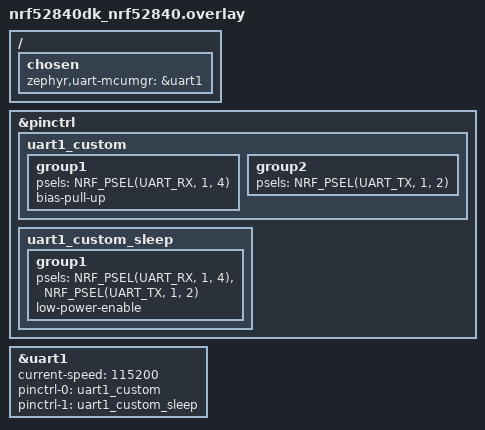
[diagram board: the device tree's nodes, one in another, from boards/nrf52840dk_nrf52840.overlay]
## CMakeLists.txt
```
cmake_minimum_required(VERSION 3.20.0)
# Top-level CMakeLists.txt for the skeleton application.
#
# Copyright (c) 2017 Open Source Foundries Limited
#
# SPDX-License-Identifier: Apache-2.0
#
# This provides a basic application structure suitable for communication using
# mcumgr.  It can be used as a starting point for new applications.

# Standard Zephyr application boilerplate.
find_package(Zephyr REQUIRED HINTS $ENV{ZEPHYR_BASE})
project(rid0)

target_sources(app PRIVATE src/main.c)
target_sources_ifdef(CONFIG_MCUMGR_TRANSPORT_BT app PRIVATE src/bluetooth.c)
target_sources(app PRIVATE src/central.c)
target_sources(app PRIVATE src/common.c)
target_sources(app PRIVATE src/uart.c)
target_sources(app PRIVATE src/mcumgr.c)
```

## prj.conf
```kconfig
# 启用蓝牙主机
CONFIG_BT_CENTRAL=y
CONFIG_LOG=y
CONFIG_BT_SMP=y
CONFIG_BT_GATT_CLIENT=y
CONFIG_CBPRINTF_FP_SUPPORT=y
CONFIG_BT_EXT_ADV=y

# 启用MCUmgr事件回调
CONFIG_MCUMGR_MGMT_NOTIFICATION_HOOKS=y
CONFIG_MCUMGR_GRP_IMG_UPLOAD_CHECK_HOOK=y
CONFIG_MCUMGR_GRP_IMG_STATUS_HOOKS=y

# 启用 UART1 驱动
CONFIG_SERIAL=y

#启用UART1作为升级串口
CONFIG_CONSOLE=y
CONFIG_UART_ASYNC_API=y
CONFIG_UART_0_ASYNC=y

#开启串口传输固件
CONFIG_BASE64=y
CONFIG_MCUMGR_TRANSPORT_UART=y
CONFIG_MCUMGR_TRANSPORT_UART_MTU=1024
CONFIG_MCUMGR_TRANSPORT_SHELL_MTU=1024

# Enable MCUmgr and dependencies.
CONFIG_NET_BUF=y
CONFIG_ZCBOR=y
CONFIG_CRC=y
CONFIG_MCUMGR=y
CONFIG_STREAM_FLASH=y
CONFIG_FLASH_MAP=y

# Some command handlers require a large stack.
CONFIG_SYSTEM_WORKQUEUE_STACK_SIZE=2304
CONFIG_MAIN_STACK_SIZE=2176

# Ensure an MCUboot-compatible binary is generated.
CONFIG_BOOTLOADER_MCUBOOT=y
#Include MCUMGR and the dependencies in the build
CONFIG_BT=y
CONFIG_BT_BROADCASTER=n
CONFIG_BT_OBSERVER=y
CONFIG_LOG=y
CONFIG_BT_PERIPHERAL=n
CONFIG_NCS_SAMPLE_MCUMGR_BT_OTA_DFU=n
CONFIG_MCUMGR_TRANSPORT_BT=n     # BLE升级

# Enable flash operations.
CONFIG_FLASH=y

# Required by the `taskstat` command.
CONFIG_THREAD_MONITOR=y

# Support for taskstat command
CONFIG_MCUMGR_GRP_OS_TASKSTAT=y

# Enable statistics and statistic names.
CONFIG_STATS=y
CONFIG_STATS_NAMES=y

# Enable most core commands.
CONFIG_FLASH=y
CONFIG_IMG_MANAGER=y
CONFIG_MCUMGR_GRP_IMG=y
CONFIG_MCUMGR_GRP_OS=y
CONFIG_MCUMGR_GRP_STAT=y

# Enable logging
CONFIG_LOG=y
CONFIG_MCUBOOT_UTIL_LOG_LEVEL_WRN=y

# Disable debug logging
CONFIG_LOG_MAX_LEVEL=3
```

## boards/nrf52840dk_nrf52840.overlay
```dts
/* RID0 — uart1 引脚: TX=P1.02, RX=P1.04 */
/* mcumgr DFU on uart1 */

/ {
	chosen {
		zephyr,uart-mcumgr = &uart1;
	};
};

&pinctrl {
	uart1_custom: uart1_custom {
		group1 {
			psels = <NRF_PSEL(UART_RX, 1, 4)>;
			bias-pull-up;
		};
		group2 {
			psels = <NRF_PSEL(UART_TX, 1, 2)>;
		};
	};
	uart1_custom_sleep: uart1_custom_sleep {
		group1 {
			psels = <NRF_PSEL(UART_RX, 1, 4)>,
				<NRF_PSEL(UART_TX, 1, 2)>;
			low-power-enable;
		};
	};
};

&uart1 {
	status = "okay";
	current-speed = <115200>;
	pinctrl-0 = <&uart1_custom>;
	pinctrl-1 = <&uart1_custom_sleep>;
	pinctrl-names = "default", "sleep";
};
```

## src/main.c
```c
/*
 * Copyright (c) 2012-2014 Wind River Systems, Inc.
 * Copyright (c) 2020 Prevas A/S
 *
 * SPDX-License-Identifier: Apache-2.0
 */

#include <zephyr/kernel.h>
#include <zephyr/stats/stats.h>
#include <zephyr/usb/usb_device.h>
#ifdef CONFIG_MCUMGR_GRP_FS
#include <zephyr/device.h>
#include <zephyr/fs/fs.h>
#include <zephyr/fs/littlefs.h>
#endif
#ifdef CONFIG_MCUMGR_GRP_STAT
#include <zephyr/mgmt/mcumgr/grp/stat_mgmt/stat_mgmt.h>
#endif

#define LOG_LEVEL LOG_LEVEL_DBG
#include <zephyr/logging/log.h>
LOG_MODULE_REGISTER(smp_sample);

#include "common.h"

#define STORAGE_PARTITION_LABEL	storage_partition
#define STORAGE_PARTITION_ID	FIXED_PARTITION_ID(STORAGE_PARTITION_LABEL)

/* Define an example stats group; approximates seconds since boot. */
STATS_SECT_START(smp_svr_stats)
STATS_SECT_ENTRY(ticks)
STATS_SECT_END;

/* Assign a name to the `ticks` stat. */
STATS_NAME_START(smp_svr_stats)
STATS_NAME(smp_svr_stats, ticks)
STATS_NAME_END(smp_svr_stats);

/* Define an instance of the stats group. */
STATS_SECT_DECL(smp_svr_stats) smp_svr_stats;


int main(void)
{
	int rc = STATS_INIT_AND_REG(smp_svr_stats, STATS_SIZE_32,
				    "smp_svr_stats");

	if (rc < 0) {
		LOG_ERR("Error initializing stats system [%d]", rc);
	}

#ifdef CONFIG_MCUMGR_TRANSPORT_BT
	//start_smp_bluetooth_adverts();
#endif

	if (IS_ENABLED(CONFIG_USB_DEVICE_STACK)) {
		rc = usb_enable(NULL);
		/* Ignore EALREADY error as USB CDC is likely already initialised */
		if (rc != 0 && rc != -EALREADY) {
			LOG_ERR("Failed to enable USB");
			return 0;
		}
	}
	/* using __TIME__ ensure that a new binary will be built on every
	 * compile which is convenient when testing firmware upgrade.
	 */
	LOG_INF("build time: " __DATE__ " " __TIME__);

	/* The system work queue handles all incoming mcumgr requests.  Let the
	 * main thread idle while the mcumgr server runs.
	 */
	//注册DFU回调
	mcumgr_callback_register();
	//蓝牙扫描
	central_scan_adv();
	// 初始化 UART1
    uart_init(uart0);
	uart_init(uart1);
	while (1) {
		k_sleep(K_MSEC(1000));
		STATS_INC(smp_svr_stats, ticks);
	}
	return 0;
}
```

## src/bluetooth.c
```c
/*
 * Copyright (c) 2012-2014 Wind River Systems, Inc.
 * Copyright (c) 2020 Prevas A/S
 *
 * SPDX-License-Identifier: Apache-2.0
 */

#include <zephyr/bluetooth/bluetooth.h>
#include <zephyr/bluetooth/conn.h>
#include <zephyr/bluetooth/gatt.h>
#include <zephyr/bluetooth/hci.h>
#include <zephyr/mgmt/mcumgr/transport/smp_bt.h>

#define LOG_LEVEL LOG_LEVEL_DBG
#include <zephyr/logging/log.h>
LOG_MODULE_REGISTER(smp_bt_sample);

static struct k_work advertise_work;

static const struct bt_data ad[] = {
	BT_DATA_BYTES(BT_DATA_FLAGS, (BT_LE_AD_GENERAL | BT_LE_AD_NO_BREDR)),
	BT_DATA_BYTES(BT_DATA_UUID128_ALL, SMP_BT_SVC_UUID_VAL),
};

static const struct bt_data sd[] = {
	BT_DATA(BT_DATA_NAME_COMPLETE, CONFIG_BT_DEVICE_NAME, sizeof(CONFIG_BT_DEVICE_NAME) - 1),
};

static void advertise(struct k_work *work)
{
	int rc;

	rc = bt_le_adv_start(BT_LE_ADV_CONN_FAST_1, ad, ARRAY_SIZE(ad), sd, ARRAY_SIZE(sd));
	if (rc) {
		LOG_ERR("Advertising failed to start (rc %d)", rc);
		return;
	}

	LOG_INF("Advertising successfully started");
}

static void connected(struct bt_conn *conn, uint8_t err)
{
	if (err) {
		LOG_ERR("Connection failed, err 0x%02x %s", err, bt_hci_err_to_str(err));
		k_work_submit(&advertise_work);
	} else {
		LOG_INF("Connected");
	}
}

static void disconnected(struct bt_conn *conn, uint8_t reason)
{
	LOG_INF("Disconnected, reason 0x%02x %s", reason, bt_hci_err_to_str(reason));
}

static void on_conn_recycled(void)
{
	k_work_submit(&advertise_work);
}

BT_CONN_CB_DEFINE(conn_callbacks) = {
	.connected = connected,
	.disconnected = disconnected,
	.recycled = on_conn_recycled,
};

static void bt_ready(int err)
{
	if (err != 0) {
		LOG_ERR("Bluetooth failed to initialise: %d", err);
	} else {
		k_work_submit(&advertise_work);
	}
}

void start_smp_bluetooth_adverts(void)
{
	int rc;

	k_work_init(&advertise_work, advertise);
	rc = bt_enable(bt_ready);

	if (rc != 0) {
		LOG_ERR("Bluetooth enable failed: %d", rc);
	}
}
```

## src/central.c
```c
/* main.c - Application main entry point */

/*
 * Copyright (c) 2020 SixOctets Systems
 *
 * SPDX-License-Identifier: Apache-2.0
 */

#include "common.h"
#include <errno.h>
#include <stddef.h>
#include <stdio.h>
#include <zephyr/bluetooth/bluetooth.h>
#include <zephyr/bluetooth/conn.h>
#include <zephyr/bluetooth/gatt.h>
#include <zephyr/bluetooth/hci.h>
#include <zephyr/bluetooth/uuid.h>
#include <zephyr/kernel.h>
#include <zephyr/sys/byteorder.h>
#include <zephyr/sys/printk.h>


static int scan_start(void);

static struct bt_conn *default_conn;
static struct bt_uuid_16 discover_uuid = BT_UUID_INIT_16(0);
static struct bt_gatt_discover_params discover_params;
static struct bt_gatt_subscribe_params subscribe_params;

static double pow(double x, double y)
{
    double result = 1;

    if (y < 0)
    {
        y = -y;
        while (y--)
        {
            result /= x;
        }
    }
    else
    {
        while (y--)
        {
            result *= x;
        }
    }

    return result;
}

static uint8_t notify_func(struct bt_conn *conn, struct bt_gatt_subscribe_params *params, const void *data, uint16_t length)
{
    double temperature;
    uint32_t mantissa;
    int8_t exponent;

    if (!data)
    {
        printk("[UNSUBSCRIBED]\n");
        params->value_handle = 0U;
        return BT_GATT_ITER_STOP;
    }

    /* temperature value display */
    mantissa = sys_get_le24(&((uint8_t *)data)[1]);
    exponent = ((uint8_t *)data)[4];
    temperature = (double)mantissa * pow(10, exponent);

    printf("Temperature %gC.\n", temperature);

    return BT_GATT_ITER_CONTINUE;
}

static uint8_t discover_func(struct bt_conn *conn, const struct bt_gatt_attr *attr, struct bt_gatt_discover_params *params)
{
    int err;

    if (!attr)
    {
        printk("Discover complete\n");
        (void)memset(params, 0, sizeof(*params));
        return BT_GATT_ITER_STOP;
    }

    printk("[ATTRIBUTE] handle %u\n", attr->handle);

    if (!bt_uuid_cmp(discover_params.uuid, BT_UUID_HTS))
    {
        memcpy(&discover_uuid, BT_UUID_HTS_MEASUREMENT, sizeof(discover_uuid));
        discover_params.uuid = &discover_uuid.uuid;
        discover_params.start_handle = attr->handle + 1;
        discover_params.type = BT_GATT_DISCOVER_CHARACTERISTIC;

        err = bt_gatt_discover(conn, &discover_params);
        if (err)
        {
            printk("Discover failed (err %d)\n", err);
        }
    }
    else if (!bt_uuid_cmp(discover_params.uuid, BT_UUID_HTS_MEASUREMENT))
    {
        memcpy(&discover_uuid, BT_UUID_GATT_CCC, sizeof(discover_uuid));
        discover_params.uuid = &discover_uuid.uuid;
        discover_params.start_handle = attr->handle + 2;
        discover_params.type = BT_GATT_DISCOVER_DESCRIPTOR;
        subscribe_params.value_handle = bt_gatt_attr_value_handle(attr);

        err = bt_gatt_discover(conn, &discover_params);
        if (err)
        {
            printk("Discover failed (err %d)\n", err);
        }
    }
    else
    {
        subscribe_params.notify = notify_func;
        subscribe_params.value = BT_GATT_CCC_INDICATE;
        subscribe_params.ccc_handle = attr->handle;

        err = bt_gatt_subscribe(conn, &subscribe_params);
        if (err && err != -EALREADY)
        {
            printk("Subscribe failed (err %d)\n", err);
        }
        else
        {
            printk("[SUBSCRIBED]\n");
        }

        return BT_GATT_ITER_STOP;
    }

    return BT_GATT_ITER_STOP;
}

static void connected(struct bt_conn *conn, uint8_t conn_err)
{
    char addr[BT_ADDR_LE_STR_LEN];
    int err;

    bt_addr_le_to_str(bt_conn_get_dst(conn), addr, sizeof(addr));

    if (conn_err)
    {
        printk("Failed to connect to %s (%u)\n", addr, conn_err);

        bt_conn_unref(default_conn);
        default_conn = NULL;

        scan_start();
        return;
    }

    printk("Connected: %s\n", addr);

    if (conn == default_conn)
    {
        memcpy(&discover_uuid, BT_UUID_HTS, sizeof(discover_uuid));
        discover_params.uuid = &discover_uuid.uuid;
        discover_params.func = discover_func;
        discover_params.start_handle = BT_ATT_FIRST_ATTRIBUTE_HANDLE;
        discover_params.end_handle = BT_ATT_LAST_ATTRIBUTE_HANDLE;
        discover_params.type = BT_GATT_DISCOVER_PRIMARY;

        err = bt_gatt_discover(default_conn, &discover_params);
        if (err)
        {
            printk("Discover failed(err %d)\n", err);
            return;
        }
    }
}

static bool eir_found(struct bt_data *data, void *user_data)
{
    bt_addr_le_t *addr = user_data;
    int i;

    printk("[AD]: %u data_len %u\n", data->type, data->data_len);

    switch (data->type)
    {
    case BT_DATA_UUID16_SOME:
    case BT_DATA_UUID16_ALL:
        if (data->data_len % sizeof(uint16_t) != 0U)
        {
            printk("AD malformed\n");
            return true;
        }

        for (i = 0; i < data->data_len; i += sizeof(uint16_t))
        {
            const struct bt_uuid *uuid;
            uint16_t u16;
            int err;

            memcpy(&u16, &data->data[i], sizeof(u16));
            uuid = BT_UUID_DECLARE_16(sys_le16_to_cpu(u16));
            if (bt_uuid_cmp(uuid, BT_UUID_HTS))
            {
                continue;
            }

            err = bt_le_scan_stop();
            if (err)
            {
                printk("Stop LE scan failed (err %d)\n", err);
                continue;
            }

            err = bt_conn_le_create(addr, BT_CONN_LE_CREATE_CONN, BT_LE_CONN_PARAM_DEFAULT, &default_conn);
            if (err)
            {
                printk("Create connection failed (err %d)\n", err);
                scan_start();
            }

            return false;
        }
    }

    return true;
}

// 定义结构体
typedef struct rid
{
    // 数据域
    uint8_t msg_type;       // 报文类型
    uint8_t base_msg[31];   // 基本ID报文0x0
    uint8_t pos_msg[31];    // 位置向量报文0x1
    uint8_t diy_msg[31];    // 自定义保留报文0x2
    uint8_t run_msg[31];    // 运行描述报文0x3
    uint8_t sys_msg[31];    // 系统报文0x4
    uint8_t ope_msg[31];    // 操作人员报文0x5
    uint8_t mac[6];         // 蓝牙mac地址
} RID;

static void device_found(const bt_addr_le_t *addr, int8_t rssi, uint8_t type,
                         struct net_buf_simple *ad)
{
    char dev[BT_ADDR_LE_STR_LEN];
    RID rid_info;
    int i;

#if 1
    /* ===== 测试指标: 每秒 BLE 广播包接收数量 ===== */
    {
        static uint32_t adv_count = 0;
        static int64_t last_print_ms = 0;
        int64_t now_ms = k_uptime_get();

        adv_count++;

        if ((now_ms - last_print_ms) >= 1000) {
            printk("[ADV-STATS] adv/sec=%u\n", adv_count);
            adv_count = 0;
            last_print_ms = now_ms;
        }
    }
#else
    bt_addr_le_to_str(addr, dev, sizeof(dev));

    /* RID 数据头部比对 */
    if (!(ad->data[1] == 0x16 && ad->data[2] == 0xFA &&
          ad->data[3] == 0xFF && ad->data[4] == 0x0D && ad->len > 5)) {
        return;
    }

    printk("[DEVICE]: %s, AD evt type %u, AD data len %u, RSSI %i adv %s\n",
           dev, type, ad->len, rssi, Util_convertHex2Str(ad->data, ad->len));

    if (ad->len > 0x1E) {
        /* ===== GB 46750-2025 扩展格式 (>31字节) ===== */
        /* 输出格式: AABB + MAC(6B) + GB TLV(直接0xFF开头) + CCDD */
        /* BLE AD structure 在 C738VR 侧不需要，直接传 TLV 即可 */
        /* buf 大小 = 2(头) + 6(MAC) + (ad->len - 6) + 2(尾) */
        /* ad->data 结构: [AD len][0x16][0xFAFF][0x0D][counter][TLV...] */
        /* 跳过前 6 字节 BLE AD structure，只取 TLV */
        uint8_t tlv_offset = 6;  /* 跳过 AD len + type + UUID + ODID + counter */
        if (ad->len <= tlv_offset) return;
        uint16_t tlv_len = ad->len - tlv_offset;
        uint8_t buf[265];
        uint8_t buf_size = 2 + 6 + tlv_len + 2;

        buf[0] = 0xAA;
        buf[1] = 0xBB;
        memcpy(&buf[2], addr->a.val, 6);   /* MAC 6 字节 */
        memcpy(&buf[2 + 6], ad->data + tlv_offset, tlv_len);  /* 只传 TLV */
        buf[2 + 6 + tlv_len]     = 0xCC;
        buf[2 + 6 + tlv_len + 1] = 0xDD;

        UART_WriteData(0, buf, buf_size);
        UART_WriteData(1, buf, buf_size);

        /* 打印关键字段用于调试 */
        uint8_t gb_type  = ad->data[tlv_offset];     /* 0xFF */
        uint8_t version  = ad->data[tlv_offset + 1]; /* 版本号 */
        uint8_t gb_len   = ad->data[tlv_offset + 2]; /* 数据长度 */
        printk("[GB46750] MAC=%s type=0x%02X ver=0x%02X gb_len=%u tlv=%u\n",
               dev, gb_type, version, gb_len, tlv_len);

    } else {
        /* ===== 原有 31 字节 RID 格式 (msg_type 0x0~0x5) ===== */
        uint8_t buf[41] = {0xAA, 0xBB};
        uint8_t msg_type = ad->data[6] >> 4;
        uint8_t *msg_ptr = NULL;

        switch (msg_type) {
        case 0x0: rid_info.msg_type = 0x0; msg_ptr = rid_info.base_msg; break;
        case 0x1: rid_info.msg_type = 0x1; msg_ptr = rid_info.pos_msg;   break;
        case 0x2: rid_info.msg_type = 0x2; msg_ptr = rid_info.diy_msg;   break;
        case 0x3: rid_info.msg_type = 0x3; msg_ptr = rid_info.run_msg;   break;
        case 0x4: rid_info.msg_type = 0x4; msg_ptr = rid_info.sys_msg;   break;
        case 0x5: rid_info.msg_type = 0x5; msg_ptr = rid_info.ope_msg;   break;
        default:
            printk("[RID] unknown msg_type 0x%x\n", msg_type);
            return;
        }

        memcpy(rid_info.mac, addr->a.val, sizeof(addr->a.val));
        memcpy(msg_ptr, ad->data, 31);

        /* 组装: AABB + MAC(6B) + encoded_data(25B 跳过 BLE AD structure) + CCDD */
        /* ad->data = [AD len][0x16][0xFAFF][0x0D][counter][encoded 25B], 共 31B */
        /* 跳过前 6 字节 BLE AD structure，只传 encoded_data 给 C738VR */
        uint8_t encoded_offset = 6;
        uint8_t *encoded = msg_ptr + encoded_offset;
        for (i = 0; i < sizeof(addr->a.val) + 25 + 2; i++) {
            if (i >= 8) {
                buf[i] = encoded[i - 8];
            } else {
                buf[i + 2] = rid_info.mac[i];
            }
        }
        buf[2 + sizeof(addr->a.val) + 25]     = 0xCC;
        buf[2 + sizeof(addr->a.val) + 25 + 1] = 0xDD;

        UART_WriteData(0, buf, 2 + 6 + 25 + 2);
        UART_WriteData(1, buf, 2 + 6 + 25 + 2);
    }
#endif
}

static int scan_start(void)
{
    /* Use active scanning and disable duplicate filtering to handle any
     * devices that might update their advertising data at runtime.
     */
    struct bt_le_scan_param scan_param = {
        .type = BT_LE_SCAN_TYPE_ACTIVE,
        .options = BT_LE_SCAN_OPT_NONE,
        .interval = BT_GAP_SCAN_FAST_INTERVAL,
        .window = BT_GAP_SCAN_FAST_WINDOW,
    };

    return bt_le_scan_start(&scan_param, device_found);
}

static void disconnected(struct bt_conn *conn, uint8_t reason)
{
    char addr[BT_ADDR_LE_STR_LEN];
    int err;

    bt_addr_le_to_str(bt_conn_get_dst(conn), addr, sizeof(addr));

    printk("Disconnected: %s, reason 0x%02x %s\n", addr, reason, bt_hci_err_to_str(reason));

    if (default_conn != conn)
    {
        return;
    }

    bt_conn_unref(default_conn);
    default_conn = NULL;

    err = scan_start();
    if (err)
    {
        printk("Scanning failed to start (err %d)\n", err);
    }
}

BT_CONN_CB_DEFINE(conn_callbacks) = {
    .connected = connected,
    .disconnected = disconnected,
};

int central_scan_adv(void)
{
    int err;

    err = bt_enable(NULL);
    if (err)
    {
        printk("Bluetooth init failed (err %d)\n", err);
        return 0;
    }

    printk("Bluetooth initialized\n");

    err = scan_start();

    if (err)
    {
        printk("Scanning failed to start (err %d)\n", err);
        return 0;
    }

    printk("Scanning successfully started\n");
    printk("ota test 9\n");
    return 0;
}

void stop_scan(void)
{
    int err = bt_le_scan_stop();
    if (err)
    {
        //printk("Stop LE scan failed (err %d)\n", err);
    }
    //printk("stop scan success\r\n");
}
```

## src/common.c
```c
#include <stdio.h>
#include <stdint.h>
#include <stdbool.h>
#include "common.h"

#define B_ADDR_LEN    6

/*********************************************************************
 * @fn      Util_convertBdAddr2Str
 *
 * @brief   Convert Bluetooth address to string. Only needed when
 *          LCD display is used.
 *
 * @param   pAddr - BD address
 *
 * @return  BD address as a string
 */
char *Util_convertBdAddr2Str(uint8_t *pAddr)
{
  uint8_t     charCnt;
  char        hex[] = "0123456789ABCDEF";
  static char str[(2*B_ADDR_LEN)+3];
  char        *pStr = str;

  *pStr++ = '0';
  *pStr++ = 'x';

  // Start from end of addr
  pAddr += B_ADDR_LEN;

  for (charCnt = B_ADDR_LEN; charCnt > 0; charCnt--)
  {
    *pStr++ = hex[*--pAddr >> 4];
    *pStr++ = hex[*pAddr & 0x0F];
  }
  pStr = NULL;

  return str;
}

/*********************************************************************
 * @fn      Util_convertHex2Str
 *
 * @brief   将HEX转成String，用于转化广播数据和扫描回调数据
 *
 * @param   Hex - Hex
 *          len - Hex len
 *
 * @return  Hex as a string
 */
#define MAX_AD_DATA_LEN 255
char *Util_convertHex2Str(uint8_t *Hex, uint16_t Len)
{
  uint8_t     charCnt;
  char        hex[] = "0123456789ABCDEF";
  static char str[(2*MAX_AD_DATA_LEN)+4];    // 广播数据
  char        *pStr = str;

  *pStr++ = '0';
  *pStr++ = 'x';

  for (charCnt = Len; charCnt > 0; charCnt--)
  {
    *pStr++ = hex[*Hex >> 4];
    *pStr++ = hex[*Hex++ & 0x0F];
  }
  pStr = NULL;

  str[2*Len+2] = '\0';
  return str;
}
```

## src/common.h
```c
#ifndef COMMON_H
#define COMMON_H

#include <stdint.h>
#include <zephyr/device.h>
#include <zephyr/devicetree.h>
#include <zephyr/drivers/uart.h>
#include <zephyr/kernel.h>        // 添加printk所需头文件

/*********************************************************************
 * @fn      Util_convertBdAddr2Str
 *
 * @brief   Convert Bluetooth address to string. Only needed when
 *          LCD display is used.
 *
 * @param   pAddr - BD address
 *
 * @return  BD address as a string
 */
extern char *Util_convertBdAddr2Str(uint8_t *pAddr);

/*********************************************************************
 * @fn      Util_convertHex2Str
 *
 * @brief   将HEX转成String
 *
 * @param   Hex - Hex
 *          len - Hex len
 *
 * @return  Hex as a string
 */
extern char *Util_convertHex2Str(uint8_t *Hex, uint16_t Len);

void start_smp_bluetooth_adverts(void);
int central_scan_adv(void);
void stop_scan(void);

extern const struct device *uart0;
extern const struct device *uart1;
void uart_init(const struct device *dev);  // 声明初始化函数
void UART_WriteData(uint8_t uartNum, uint8_t *pData, uint16_t dataLen);
extern bool scan_active;
void mcumgr_callback_register(void);

#endif // COMMON_H
```

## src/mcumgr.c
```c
#include <zephyr/mgmt/mcumgr/mgmt/mgmt.h>
#include <zephyr/mgmt/mcumgr/mgmt/callbacks.h>
#include <zephyr/mgmt/mcumgr/grp/img_mgmt/img_mgmt_callbacks.h>
#include <zephyr/bluetooth/bluetooth.h>
#include <zephyr/bluetooth/gap.h>
#include "common.h"

/* 全局扫描控制标志 */
bool scan_active = true;
/* 回调函数实现 */
static enum mgmt_cb_return img_mgmt_callback(uint32_t event, enum mgmt_cb_return prev_status,
	int32_t *rc, uint16_t *group, bool *abort_more, void *data, size_t data_size)
{
    switch (event) {
	case MGMT_EVT_OP_IMG_MGMT_DFU_CHUNK:
	    scan_active = false;
		stop_scan();
        break;

    case MGMT_EVT_OP_IMG_MGMT_DFU_STARTED:
        scan_active = false;

        break;
        
    case MGMT_EVT_OP_IMG_MGMT_DFU_STOPPED:
        scan_active = true;

        break;
        
    default:
        /* 忽略其他事件 */
        break;
    }
    
    return MGMT_ERR_EOK;
}

/* 注册DFU回调 */
static struct mgmt_callback img_mgmt_cb_chunk = {
    .callback = img_mgmt_callback,
    .event_id = MGMT_EVT_OP_IMG_MGMT_DFU_CHUNK
};
static struct mgmt_callback img_mgmt_cb_start = {
    .callback = img_mgmt_callback,
    .event_id = MGMT_EVT_OP_IMG_MGMT_DFU_STARTED
};
static struct mgmt_callback img_mgmt_cb_stop = {
    .callback = img_mgmt_callback,
    .event_id = MGMT_EVT_OP_IMG_MGMT_DFU_STOPPED
};

void mcumgr_callback_register(void)
{
	mgmt_callback_register(&img_mgmt_cb_chunk);
	mgmt_callback_register(&img_mgmt_cb_start);
	mgmt_callback_register(&img_mgmt_cb_stop);
}
```

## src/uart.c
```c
// uart.c
#include "common.h"
// 声明设备指针（全局可见）
const struct device *uart0;
const struct device *uart1;

void uart_init(const struct device *uart_dev) {
    if (uart_dev == NULL) {
        printk("UART device is NULL\n");
        return;
    }
    if (!device_is_ready(uart_dev)) {
        printk("UART device not ready\n");
        return;
    }
    // 可选：动态配置波特率等
}

// 串口发送函数
void UART_WriteData(uint8_t uartNum, uint8_t *pData, uint16_t dataLen)
{
    const struct device *target_uart = NULL;
    
    // 选择目标UART设备
    switch(uartNum) {
        case 0:
            target_uart = uart0;
            break;
        case 1:
            target_uart = uart1;
            break;
        default:
            printk("Invalid UART number: %d\n", uartNum);
            return;
    }
    
    // 检查设备是否就绪
    if (target_uart == NULL || !device_is_ready(target_uart)) {
        printk("UART%d not ready\n", uartNum);
        return;
    }
    
    // 发送数据
    for (uint16_t i = 0; i < dataLen; i++) {
        uart_poll_out(target_uart, pData[i]);
    }
}

// 初始化设备指针（在文件内完成）
static int uart_devices_init(void) {
    
    uart0 = DEVICE_DT_GET(DT_NODELABEL(uart0));
    uart1 = DEVICE_DT_GET(DT_NODELABEL(uart1));
    return 0;
}
SYS_INIT(uart_devices_init, POST_KERNEL, CONFIG_APPLICATION_INIT_PRIORITY);
```
